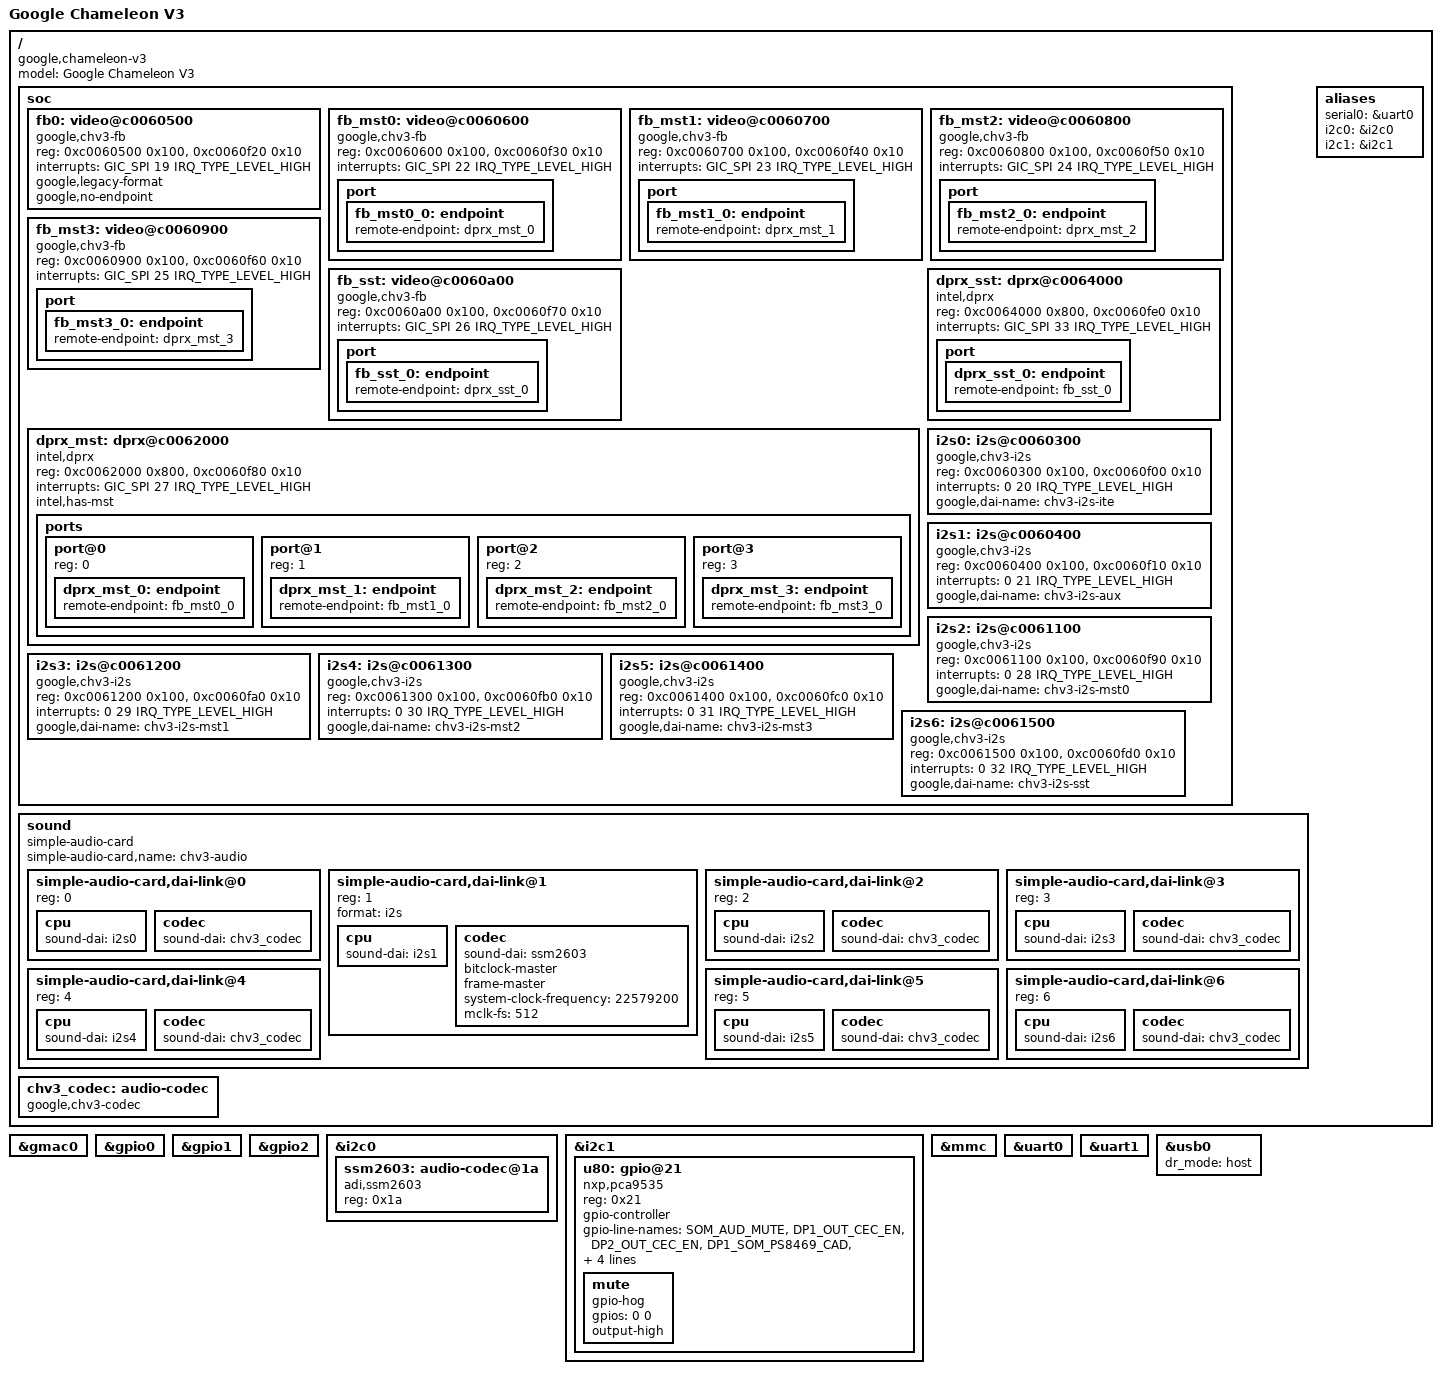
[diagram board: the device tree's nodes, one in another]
// SPDX-License-Identifier: GPL-2.0
/*
 * Copyright 2022 Google LLC
 */
/dts-v1/;
#include "socfpga_arria10_mercury_aa1.dtsi"

/ {
	model = "Google Chameleon V3";
	compatible = "google,chameleon-v3", "enclustra,mercury-aa1",
		     "altr,socfpga-arria10", "altr,socfpga";

	soc {
		fb0: video@c0060500 {
			compatible = "google,chv3-fb";
			reg = <0xc0060500 0x100>,
			      <0xc0060f20 0x10>;
			interrupts = <GIC_SPI 19 IRQ_TYPE_LEVEL_HIGH>;
			google,legacy-format;
			google,no-endpoint;
		};

		fb_mst0: video@c0060600 {
			compatible = "google,chv3-fb";
			reg = <0xc0060600 0x100>,
			      <0xc0060f30 0x10>;
			interrupts = <GIC_SPI 22 IRQ_TYPE_LEVEL_HIGH>;

			port {
				fb_mst0_0: endpoint {
					remote-endpoint = <&dprx_mst_0>;
				};
			};
		};

		fb_mst1: video@c0060700 {
			compatible = "google,chv3-fb";
			reg = <0xc0060700 0x100>,
			      <0xc0060f40 0x10>;
			interrupts = <GIC_SPI 23 IRQ_TYPE_LEVEL_HIGH>;

			port {
				fb_mst1_0: endpoint {
					remote-endpoint = <&dprx_mst_1>;
				};
			};
		};

		fb_mst2: video@c0060800 {
			compatible = "google,chv3-fb";
			reg = <0xc0060800 0x100>,
			      <0xc0060f50 0x10>;
			interrupts = <GIC_SPI 24 IRQ_TYPE_LEVEL_HIGH>;

			port {
				fb_mst2_0: endpoint {
					remote-endpoint = <&dprx_mst_2>;
				};
			};
		};

		fb_mst3: video@c0060900 {
			compatible = "google,chv3-fb";
			reg = <0xc0060900 0x100>,
			      <0xc0060f60 0x10>;
			interrupts = <GIC_SPI 25 IRQ_TYPE_LEVEL_HIGH>;

			port {
				fb_mst3_0: endpoint {
					remote-endpoint = <&dprx_mst_3>;
				};
			};
		};

		fb_sst: video@c0060a00 {
			compatible = "google,chv3-fb";
			reg = <0xc0060a00 0x100>,
			      <0xc0060f70 0x10>;
			interrupts = <GIC_SPI 26 IRQ_TYPE_LEVEL_HIGH>;

			port {
				fb_sst_0: endpoint {
					remote-endpoint = <&dprx_sst_0>;
				};
			};
		};

		dprx_mst: dprx@c0062000 {
			compatible = "intel,dprx";
			reg = <0xc0062000 0x800>,
			      <0xc0060f80 0x10>;
			interrupts = <GIC_SPI 27 IRQ_TYPE_LEVEL_HIGH>;
			intel,has-mst;

			ports {
				#address-cells = <1>;
				#size-cells = <0>;

				port@0 {
					reg = <0>;
					dprx_mst_0: endpoint {
						remote-endpoint = <&fb_mst0_0>;
					};
				};

				port@1 {
					reg = <1>;
					dprx_mst_1: endpoint {
						remote-endpoint = <&fb_mst1_0>;
					};
				};

				port@2 {
					reg = <2>;
					dprx_mst_2: endpoint {
						remote-endpoint = <&fb_mst2_0>;
					};
				};

				port@3 {
					reg = <3>;
					dprx_mst_3: endpoint {
						remote-endpoint = <&fb_mst3_0>;
					};
				};
			};
		};

		dprx_sst: dprx@c0064000 {
			compatible = "intel,dprx";
			reg = <0xc0064000 0x800>,
			      <0xc0060fe0 0x10>;
			interrupts = <GIC_SPI 33 IRQ_TYPE_LEVEL_HIGH>;

			port {
				dprx_sst_0: endpoint {
					remote-endpoint = <&fb_sst_0>;
				};
			};
		};

		i2s0: i2s@c0060300 {
			compatible = "google,chv3-i2s";
			reg = <0xc0060300 0x100>,
			      <0xc0060f00 0x10>;
			interrupts = <0 20 IRQ_TYPE_LEVEL_HIGH>;
			#sound-dai-cells = <0>;
			google,dai-name = "chv3-i2s-ite";
		};

		i2s1: i2s@c0060400 {
			compatible = "google,chv3-i2s";
			reg = <0xc0060400 0x100>,
			      <0xc0060f10 0x10>;
			interrupts = <0 21 IRQ_TYPE_LEVEL_HIGH>;
			#sound-dai-cells = <0>;
			google,dai-name = "chv3-i2s-aux";
		};

		i2s2: i2s@c0061100 {
			compatible = "google,chv3-i2s";
			reg = <0xc0061100 0x100>,
			      <0xc0060f90 0x10>;
			interrupts = <0 28 IRQ_TYPE_LEVEL_HIGH>;
			#sound-dai-cells = <0>;
			google,dai-name = "chv3-i2s-mst0";
		};

		i2s3: i2s@c0061200 {
			compatible = "google,chv3-i2s";
			reg = <0xc0061200 0x100>,
			      <0xc0060fa0 0x10>;
			interrupts = <0 29 IRQ_TYPE_LEVEL_HIGH>;
			#sound-dai-cells = <0>;
			google,dai-name = "chv3-i2s-mst1";
		};

		i2s4: i2s@c0061300 {
			compatible = "google,chv3-i2s";
			reg = <0xc0061300 0x100>,
			      <0xc0060fb0 0x10>;
			interrupts = <0 30 IRQ_TYPE_LEVEL_HIGH>;
			#sound-dai-cells = <0>;
			google,dai-name = "chv3-i2s-mst2";
		};

		i2s5: i2s@c0061400 {
			compatible = "google,chv3-i2s";
			reg = <0xc0061400 0x100>,
			      <0xc0060fc0 0x10>;
			interrupts = <0 31 IRQ_TYPE_LEVEL_HIGH>;
			#sound-dai-cells = <0>;
			google,dai-name = "chv3-i2s-mst3";
		};

		i2s6: i2s@c0061500 {
			compatible = "google,chv3-i2s";
			reg = <0xc0061500 0x100>,
			      <0xc0060fd0 0x10>;
			interrupts = <0 32 IRQ_TYPE_LEVEL_HIGH>;
			#sound-dai-cells = <0>;
			google,dai-name = "chv3-i2s-sst";
		};
	};

	sound {
		compatible = "simple-audio-card";
		simple-audio-card,name = "chv3-audio";
		#address-cells = <1>;
		#size-cells = <0>;

		simple-audio-card,dai-link@0 {
			reg = <0>;
			cpu {
				sound-dai = <&i2s0>;
			};
			codec {
				sound-dai = <&chv3_codec>;
			};
		};

		simple-audio-card,dai-link@1 {
			reg = <1>;
			format = "i2s";
			cpu {
				sound-dai = <&i2s1>;
			};
			codec {
				sound-dai = <&ssm2603>;
				bitclock-master;
				frame-master;
				system-clock-frequency = <22579200>;
				mclk-fs = <512>;
			};
		};

		simple-audio-card,dai-link@2 {
			reg = <2>;
			cpu {
				sound-dai = <&i2s2>;
			};
			codec {
				sound-dai = <&chv3_codec>;
			};
		};

		simple-audio-card,dai-link@3 {
			reg = <3>;
			cpu {
				sound-dai = <&i2s3>;
			};
			codec {
				sound-dai = <&chv3_codec>;
			};
		};

		simple-audio-card,dai-link@4 {
			reg = <4>;
			cpu {
				sound-dai = <&i2s4>;
			};
			codec {
				sound-dai = <&chv3_codec>;
			};
		};

		simple-audio-card,dai-link@5 {
			reg = <5>;
			cpu {
				sound-dai = <&i2s5>;
			};
			codec {
				sound-dai = <&chv3_codec>;
			};
		};

		simple-audio-card,dai-link@6 {
			reg = <6>;
			cpu {
				sound-dai = <&i2s6>;
			};
			codec {
				sound-dai = <&chv3_codec>;
			};
		};
	};

	chv3_codec: audio-codec {
		compatible = "google,chv3-codec";
		#sound-dai-cells = <0>;
	};

	aliases {
		serial0 = &uart0;
		i2c0 = &i2c0;
		i2c1 = &i2c1;
	};
};

&gmac0 {
	status = "okay";
};

&gpio0 {
	status = "okay";
};

&gpio1 {
	status = "okay";
};

&gpio2 {
	status = "okay";
};

&i2c0 {
	status = "okay";

	ssm2603: audio-codec@1a {
		compatible = "adi,ssm2603";
		reg = <0x1a>;
		#sound-dai-cells = <0>;
	};
};

&i2c1 {
	status = "okay";

	u80: gpio@21 {
		compatible = "nxp,pca9535";
		reg = <0x21>;
		gpio-controller;
		#gpio-cells = <2>;

		gpio-line-names =
			"SOM_AUD_MUTE",
			"DP1_OUT_CEC_EN",
			"DP2_OUT_CEC_EN",
			"DP1_SOM_PS8469_CAD",
			"DPD_SOM_PS8469_CAD",
			"DP_OUT_PWR_EN",
			"STM32_RST_L",
			"STM32_BOOT0",

			"FPGA_PROT",
			"STM32_FPGA_COMM0",
			"TP119",
			"TP120",
			"TP121",
			"TP122",
			"TP123",
			"TP124";

		mute {
			gpio-hog;
			gpios = <0 0>;
			output-high;
		};
	};
};

&mmc {
	status = "okay";
};

&uart0 {
	status = "okay";
};

&uart1 {
	status = "okay";
};

&usb0 {
	status = "okay";
	dr_mode = "host";
};
